# DA1469x register map
Vendor: Dialog; Series: DA1469x; File version: 1.2
CPU: CM33 r1p0, little endian, no MPU, FPU, 3 interrupt priority bits
Registers are 32-bit, read-write, reset 0x0 unless marked. A register's access mark holds for its fields unless they carry their own. Offsets are from the block's base; [hi:lo] are bit positions; {n}, {i} and the like mark numbered series.

## SAU — Security Attribution Unit
Base 0xE000EDD0
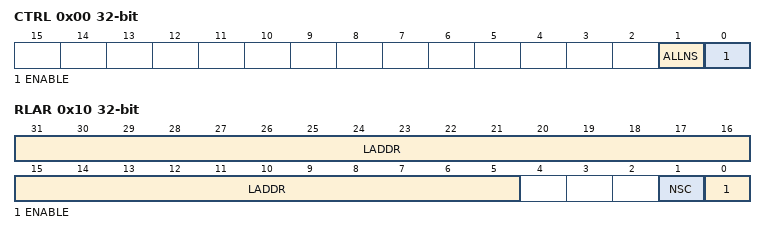
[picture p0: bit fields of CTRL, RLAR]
0x00 CTRL — Control Register
  [1] ALLNS — Security attribution if SAU disabled
    0=Secure (Memory is marked as secure); 1=Non_Secure (Memory is marked as non-secure)
  [0] ENABLE
    0=Disable (SAU is disabled); 1=Enable (SAU is enabled)
0x04 TYPE ro
  [7:0] SREGION — Number of implemented SAU regions
0x08 RNR — Region Number Register
  [7:0] REGION — Currently selected SAU region
    {v}=SAU_Region_{v} (Select SAU Region {v}) (v=0..3)
0x0C RBAR — Region Base Address Register
  [31:5] BADDR — Base Address
0x10 RLAR — Region Limit Address Register
  [31:5] LADDR — Limit Address
  [1] NSC — Non-Secure Callable
  [0] ENABLE — SAU Region enabled

## ANAMISC — ANAMISC registers
Base 0x50030B00
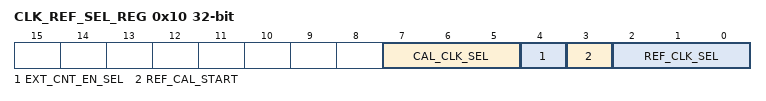
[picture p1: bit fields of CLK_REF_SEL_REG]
0x10 CLK_REF_SEL_REG — Select clock for oscillator calibration
  [7:5] CAL_CLK_SEL — Select reference clock input to be used in calibration: 0x0 : DIVN clock 0x1 : RC32K 0x2 : RC32M 0x3 : XTAL32K 0x4 : RCOSC 0x5, 0x6, 0x7: Reserved
  [4] EXT_CNT_EN_SEL — 0 : Enable XTAL_CNT counter by the REF_CLK selected by REF_CLK_SEL. 1 : Enable XTAL_CNT counter from an external input.
  [3] REF_CAL_START — Writing a '1' starts a calibration. This bit is cleared when calibration is finished, and CLK_REF_VAL is ready.
  [2:0] REF_CLK_SEL — Select clock input for calibration: 0x0 : RC32K 0x1 : RC32M 0x2 : XTAL32K 0x3 : RCX 0x4 : RCOSC
0x14 CLK_REF_CNT_REG — Count value for oscillator calibration
  [15:0] REF_CNT_VAL — Indicates the calibration time, with a decrement counter to 1.
0x18 CLK_REF_VAL_REG (reset mask 0x7FFFFFFF) — DIVN reference cycles, lower 16 bits
  [31:0] XTAL_CNT_VAL ro — Returns the number of DIVN clock cycles counted during the calibration time, defined with REF_CNT_VAL

## CHIP_VERSION — CHIP_VERSION registers
Base 0x50040200
0x00 CHIP_ID1_REG reset 0x32 — Chip identification register 1.
  [7:0] CHIP_ID1 ro — First character of device type "2522" in ASCII.
0x04 CHIP_ID2_REG reset 0x35 — Chip identification register 2.
  [7:0] CHIP_ID2 ro — Second character of device type "2522" in ASCII.
0x08 CHIP_ID3_REG reset 0x32 — Chip identification register 3.
  [7:0] CHIP_ID3 ro — Third character of device type "2522" in ASCII.
0x0C CHIP_ID4_REG reset 0x32 — Chip identification register 4.
  [7:0] CHIP_ID4 ro — Fourth character of device type "2522" in ASCII.
0x10 CHIP_SWC_REG — Software compatibility register.
  [3:0] CHIP_SWC ro — SoftWare Compatibility code. Integer (default = 0) which is incremented if a silicon change has impact on the CPU Firmware. Can be used by software developers to write silicon revision dependent code.
0x14 CHIP_REVISION_REG reset 0x41 — Chip revision register.
  [7:0] CHIP_REVISION ro — Chip version, corresponds with type number in ASCII. 0x41 = 'A', 0x42 = 'B'
0xF8 CHIP_TEST1_REG reset 0x42 — Chip test register 1.
  [7:0] CHIP_LAYOUT_REVISION ro — Chip layout revision, corresponds with type number in ASCII. 0x41 = 'A', 0x42 = 'B'
0xFC CHIP_TEST2_REG — Chip test register 2.
  [3:0] CHIP_METAL_OPTION ro — Chip metal option value.

## CMAC_TIMER_SLP — CMAC_TIMER_SLP registers
Base 0x50010400
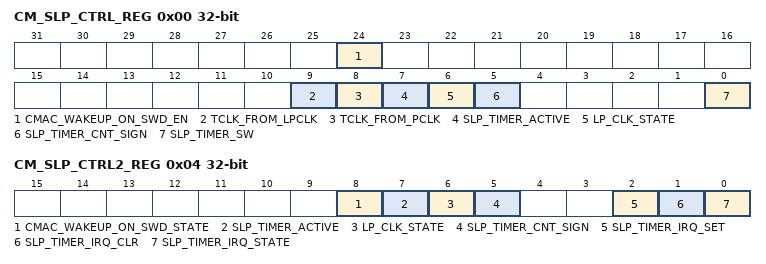
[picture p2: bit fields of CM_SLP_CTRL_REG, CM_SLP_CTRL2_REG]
0x00 CM_SLP_CTRL_REG — CMAC Sleep Control 1 (allowed to RMW)
  [24] CMAC_WAKEUP_ON_SWD_EN — If '1' then enable the generation of CMAC_WAKEUP_ON_SWD.
  [9] TCLK_FROM_LPCLK — T Clock
  [8] TCLK_FROM_PCLK — T Clock
  [7] SLP_TIMER_ACTIVE ro — Refer to SLP_TIMER_SW
  [6] LP_CLK_STATE ro
  [5] SLP_TIMER_CNT_SIGN ro — Refer to CM_SLP_CTRL2_REG->SLP_TIMER_CNT_SIGN.
  [0] SLP_TIMER_SW — Timer SW
0x04 CM_SLP_CTRL2_REG — CMAC Sleep Control 2 (no RMW)
  [8] CMAC_WAKEUP_ON_SWD_STATE — Provides the current state of CMAC_WAKEUP_ON_SWD. Writing '1' will clear this bit. Writing '0' has no effect. When CM_SLP_CTRL_REG->CMAC_WAKEUP_ON_SWD_EN=1 and the Radio Power Domain is down and SYS_CTRL_REG->CMAC_DEBUGGER_ENABLE=1 then any negative edge on SWDCLK pin will set the CMAC_WAKEUP_ON_SWD. The CMAC_WAKEUP_ON_SWD logically OR-ed with SLP_TIMER_IRQ is connected to PDC and thus it is able to wake up the CMAC, allowing the connection of CMAC Cortex with the debugger. Note: If the pins are not used as CMAC SWD, then keep SYS_CTRL_REG->CMAC_DEBUGGER_ENABLE=0 to avoid false wakeup triggers.
  [7] SLP_TIMER_ACTIVE ro — Refer to CM_SLP_CTRL_REG->SLP_TIMER_ACTIVE
  [6] LP_CLK_STATE ro — Refer to CM_SLP_CTRL_REG->LP_CLK_STATE.
  [5] SLP_TIMER_CNT_SIGN ro — Timer sign
  [2] SLP_TIMER_IRQ_SET — Writing '1' will cause the IRQ to be set. This field remains to '1' until the IRQ is set. Writing '0' has no effect. System CPU SW may use this field to force CMAC to wakeup through SLP_TIMER. Note that typically SW wakes up CMAC through the SYS2CMAC_IRQ (via PDC).
  [1] SLP_TIMER_IRQ_CLR — Writing '1' will cause the IRQ to be cleared. This field remains to '1' until the IRQ is cleared. Writing '0' has no effect. Note that clearing the IRQ is not possible as long as the Timer is "1", since the Expire event has higher priority.
  [0] SLP_TIMER_IRQ_STATE ro — Provides the current state of the CMAC Sleep Timer IRQ.
0x08 CM_SLP_TIMER_REG (reset mask 0x7FFFFFFF) — CMAC Sleep Timer
  [31:0] CM_SLP_TIMER_VALUE — Timer value
